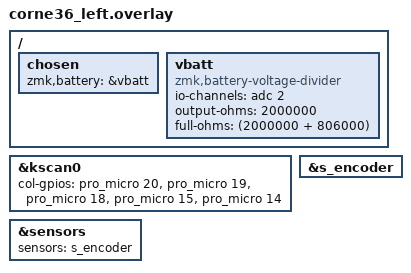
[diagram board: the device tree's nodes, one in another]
/*
 * Copyright (c) 2020 Pete Johanson
 *
 * SPDX-License-Identifier: MIT
 */

#include "corne36.dtsi"

&kscan0 {
	col-gpios
		= <&pro_micro 20 GPIO_ACTIVE_HIGH>
		, <&pro_micro 19 GPIO_ACTIVE_HIGH>
		, <&pro_micro 18 GPIO_ACTIVE_HIGH>
		, <&pro_micro 15 GPIO_ACTIVE_HIGH>
		, <&pro_micro 14 GPIO_ACTIVE_HIGH>
		;
};

/{
	chosen {
		zmk,battery = &vbatt;
	};
	vbatt: vbatt {
		compatible = "zmk,battery-voltage-divider";
		io-channels = <&adc 2>;
		output-ohms = <2000000>;
		full-ohms = <(2000000 + 806000)>;
	};
};

#include "corne36_zplit.dtsi"

&s_encoder {
    status = "okay";
};
&sensors {
		status = "okay";
		sensors = <&s_encoder>;
};
